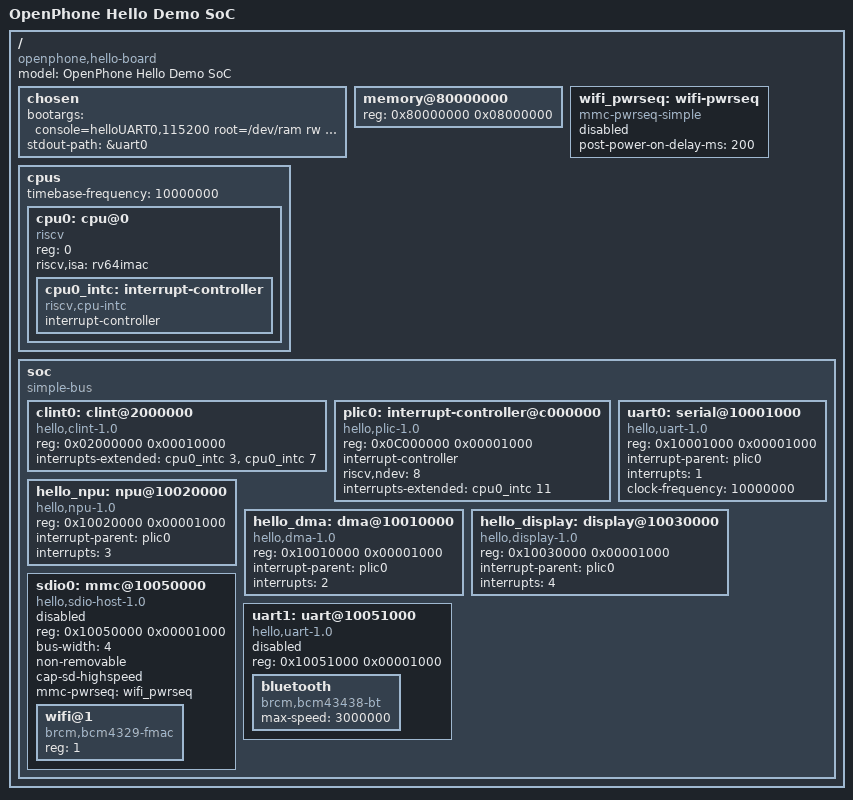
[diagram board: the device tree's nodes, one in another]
// SPDX-License-Identifier: GPL-2.0-only OR BSD-2-Clause
/*
 * OpenPhone Hello Demo - complete bootable device tree source.
 *
 * Covers the Linux-capable RISC-V scaffold described in:
 *   sw/platform/hello_platform_contract.json
 *   docs/arch/memory-map.md
 *   docs/arch/interrupts.md
 *
 * Import into an external Linux tree:
 *   cp sw/linux/dts/openphone-hello.dts \
 *      <linux>/arch/riscv/boot/dts/openphone/openphone-hello.dts
 *
 * All MMIO base addresses match the platform contract.
 */

/dts-v1/;

/ {
	compatible = "openphone,hello-board", "openphone,hello";
	model = "OpenPhone Hello Demo SoC";

	#address-cells = <1>;
	#size-cells = <1>;

	chosen {
		bootargs = "console=helloUART0,115200 root=/dev/ram rw earlycon";
		stdout-path = &uart0;
	};

	memory@80000000 {
		device_type = "memory";
		reg = <0x80000000 0x08000000>;
	};

		wifi_pwrseq: wifi-pwrseq {
			compatible = "mmc-pwrseq-simple";
			status = "disabled";
		/*
		 * Stub for a Murata Type 1DX / CYW4343W-class external module.
		 * Bind WIFI_EN/WIFI_RST_N to real GPIO phandles after hello-chip
		 * grows a GPIO/pinctrl-backed SDIO host integration.
		 */
		post-power-on-delay-ms = <200>;
			/* reset-gpios = <&gpioX N GPIO_ACTIVE_LOW>; required before enable. */
		};

		cpus {
			#address-cells = <1>;
			#size-cells = <0>;
			timebase-frequency = <10000000>;

			cpu0: cpu@0 {
				compatible = "riscv";
				device_type = "cpu";
				reg = <0>;
				riscv,isa = "rv64imac";
				status = "okay";

				cpu0_intc: interrupt-controller {
					compatible = "riscv,cpu-intc";
					interrupt-controller;
					#interrupt-cells = <1>;
				};
			};
		};

		soc {
		compatible = "simple-bus";
		#address-cells = <1>;
		#size-cells = <1>;
		ranges;

		clint0: clint@2000000 {
			compatible = "hello,clint-1.0";
			reg = <0x02000000 0x00010000>;
			interrupts-extended = <&cpu0_intc 3>, <&cpu0_intc 7>;
		};

		plic0: interrupt-controller@c000000 {
			compatible = "hello,plic-1.0";
			reg = <0x0C000000 0x00001000>;
			interrupt-controller;
			#interrupt-cells = <1>;
			riscv,ndev = <8>;
			interrupts-extended = <&cpu0_intc 11>;
		};

		uart0: serial@10001000 {
			compatible = "hello,uart-1.0";
			reg = <0x10001000 0x00001000>;
			interrupt-parent = <&plic0>;
			interrupts = <1>;
			clock-frequency = <10000000>;
			status = "okay";
		};

		hello_npu: npu@10020000 {
			compatible = "hello,npu-1.0";
			reg = <0x10020000 0x00001000>;
			interrupt-parent = <&plic0>;
			interrupts = <3>;
			status = "okay";
		};

		hello_dma: dma@10010000 {
			compatible = "hello,dma-1.0";
			reg = <0x10010000 0x00001000>;
			interrupt-parent = <&plic0>;
			interrupts = <2>;
			status = "okay";
		};

		hello_display: display@10030000 {
			compatible = "hello,display-1.0";
			reg = <0x10030000 0x00001000>;
			interrupt-parent = <&plic0>;
			interrupts = <4>;
			status = "okay";
		};

		sdio0: mmc@10050000 {
			compatible = "hello,sdio-host-1.0";
			status = "disabled";
			reg = <0x10050000 0x00001000>;
			#address-cells = <1>;
			#size-cells = <0>;
			bus-width = <4>;
			non-removable;
			cap-sd-highspeed;
			mmc-pwrseq = <&wifi_pwrseq>;
			/*
			 * WIFI_SDIO_CLK/CMD/D0/D1/D2/D3: RTL host, pinctrl,
			 * regulators, clocks, and GPIO-backed power sequencing are
			 * not implemented. Keep disabled until real phandles exist.
			 */

			wifi@1 {
				compatible = "brcm,bcm4329-fmac";
				reg = <1>;
			};
		};

			uart1: uart@10051000 {
				compatible = "hello,uart-1.0";
				status = "disabled";
				reg = <0x10051000 0x00001000>;
			/*
			 * BT_UART_TX/RX/CTS_N/RTS_N: RTL UART and flow-control
			 * pinctrl are not implemented.
			 */

			bluetooth {
				compatible = "brcm,bcm43438-bt";
				max-speed = <3000000>;
			};
		};
	};
};
